# platform_designer_hps_system_hps_0_hps register map
Vendor: default_vendor.com; File version: 0.0
Registers are 32-bit, read-write, reset 0x0 unless marked. A register's access mark holds for its fields unless they carry their own. Offsets are from the block's base; [hi:lo] are bit positions; {n}, {i} and the like mark numbered series.

## scanmgr — Registers in the Scan Manager module. These registers are implemented by an ARM JTAG-AP module from the ARM DAP. Some register and field names have been changed to match the usage in the Scan Manager. If modified, the corresponding names from the ARM documentation are provided. Only registers and fields that are relevant to the JTAG-AP use in the Scan Manager are listed.
Base 0xFFF02000
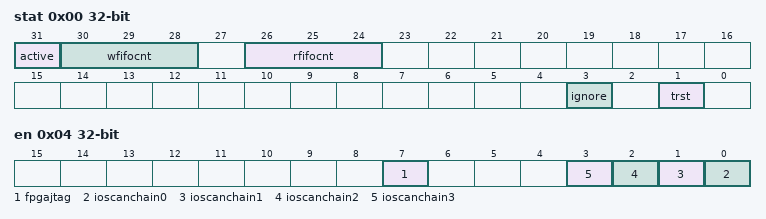
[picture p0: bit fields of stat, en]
0x00 stat (reset mask 0xFFFFFFF7) — Consist of control bit and status information.
  [31] active ro — Indicates if the Scan-Chain Engine is processing commands from the Command FIFO or not. The Scan-Chain Engine is only guaranteed to be inactive if both the ACTIVE and WFIFOCNT fields are zero. The name of this field in ARM documentation is SERACTV.
    0=possibly_inactive; 1=active
  [30:28] wfifocnt ro — Command FIFO outstanding byte count. Returns the number of command bytes held in the Command FIFO that have yet to be processed by the Scan-Chain Engine.
  [26:24] rfifocnt ro — Response FIFO outstanding byte count. Returns the number of bytes of response data available in the Response FIFO.
  [3] ignore ro — Ignore this field. Its value is undefined (may be 0 or 1). The name of this field in ARM documentation is PORTCONNECTED.
  [1] trst — Specifies the value of the nTRST signal driven to the FPGA JTAG only. The FPGA JTAG scan-chain must be enabled via the EN register to drive the value specified in this field. The nTRST signal is driven with the inverted value of this field.The nTRST signal is active low so, when this bit is set to 1, FPGA JTAG is reset. The name of this field in ARM documentation is TRST_OUT.
    0=dont_reset_fpga_jtag; 1=reset_fpga_jtag
0x04 en — This register is used to enable one of the 5 scan-chains (0-3 and 7). Only one scan-chain must be enabled at a time. A scan-chain is enabled by writing its corresponding enable field. Software must use the System Manager to put the corresponding I/O scan-chain into the frozen state before attempting to send I/O configuration data to the I/O scan-chain. Software must only write to this register when the Scan-Chain Engine is inactive.Writing this field at any other time has unpredictable results. This means that before writing to this field, software must read the STAT register and check that the ACTIVE and WFIFOCNT fields are both zero. The name of this register in ARM documentation is PSEL.
  [all] fields
    0=disable; 1=enable
  [7] fpgajtag — Used to enable or disable FPGA JTAG scan-chain.Software must use the System Manager to enable the Scan Manager to drive the FPGA JTAG before attempting to communicate with the FPGA JTAG via the Scan Manager. The name of this field in ARM documentation is PSEL7.
  [n] ioscanchain{n} (n=0..3) — Used to enable or disable I/O Scan-Chain {n} The name of this field in ARM documentation is PSEL{n}.
0x10 fifosinglebyte (reset mask 0xFFFFFF00) — Writes to the FIFO Single Byte Register write a single byte value to the command FIFO. If the command FIFO is full, the APB write operation is stalled until the command FIFO is not full. Reads from the Single Byte FIFO Register read a single byte value from the command FIFO. If the command FIFO is empty, the APB read operation is stalled until the command FIFO is not empty. See the ARM documentation for a description of the read and write values. The name of this register in ARM documentation is BWFIFO1 for writes and BRFIFO1 for reads.
  [7:0] value — Transfers single byte value to/from command FIFO
0x14 fifodoublebyte (reset mask 0xFFFF0000) — Writes to the FIFO Double Byte Register write a double byte value to the command FIFO. If the command FIFO is full, the APB write operation is stalled until the command FIFO is not full. Reads from the Double Byte FIFO Register read a double byte value from the command FIFO. If the command FIFO is empty, the APB read operation is stalled until the command FIFO is not empty. See the ARM documentation for a description of the read and write values. The name of this register in ARM documentation is BWFIFO2 for writes and BRFIFO2 for reads.
  [15:0] value — Transfers double byte value to/from command FIFO
0x18 fifotriplebyte (reset mask 0xFF000000) — Writes to the FIFO Triple Byte Register write a triple byte value to the command FIFO. If the command FIFO is full, the APB write operation is stalled until the command FIFO is not full. Reads from the Triple Byte FIFO Register read a triple byte value from the command FIFO. If the command FIFO is empty, the APB read operation is stalled until the command FIFO is not empty. See the ARM documentation for a description of the read and write values. The name of this register in ARM documentation is BWFIFO3 for writes and BRFIFO3 for reads.
  [23:0] value — Transfers triple byte value to/from command FIFO
0x1C fifoquadbyte reset not defined — Writes to the FIFO Quad Byte Register write a quad byte value to the command FIFO. If the command FIFO is full, the APB write operation is stalled until the command FIFO is not full. Reads from the Quad Byte FIFO Register read a quad byte value from the command FIFO. If the command FIFO is empty, the APB read operation is stalled until the command FIFO is not empty. See the ARM documentation for a description of the read and write values. The name of this register in ARM documentation is BWFIFO4 for writes and BRFIFO4 for reads.
  [31:0] value — Transfers quad byte value to/from command FIFO
